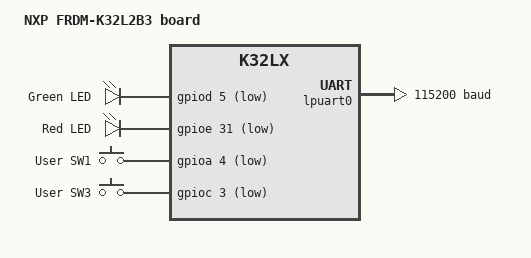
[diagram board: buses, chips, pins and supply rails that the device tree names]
/*
 * SPDX-License-Identifier: Apache-2.0
 */

/dts-v1/;

#include <nxp/nxp_k32l2b3.dtsi>
#include "frdm_k32l2b3-pinctrl.dtsi"
#include <zephyr/dt-bindings/input/input-event-codes.h>

/ {
	model = "NXP FRDM-K32L2B3 board";
	compatible = "nxp,k32l2b3", "nxp,k32lx";

	aliases {
		led0 = &green_led;
		led1 = &red_led;
		sw0 = &sw_1;
		sw1 = &sw_3;
	};

	chosen {
		zephyr,sram = &sram0;
		zephyr,flash = &flash0;
		zephyr,console = &lpuart0;
		zephyr,shell-uart = &lpuart0;
	};

	leds {
		compatible = "gpio-leds";
		green_led: led0 {
			gpios = <&gpiod 5 GPIO_ACTIVE_LOW>;
			label = "Green LED";
		};
		red_led: led1 {
			gpios = <&gpioe 31 GPIO_ACTIVE_LOW>;
			label = "Red LED";
		};
	};

	gpio_keys {
		compatible = "gpio-keys";
		sw_1: sw0 {
			label = "User SW1";
			gpios = <&gpioa 4 GPIO_ACTIVE_LOW>;
			zephyr,code = <INPUT_KEY_0>;
		};
		sw_3: sw1 {
			label = "User SW3";
			gpios = <&gpioc 3 GPIO_ACTIVE_LOW>;
			zephyr,code = <INPUT_KEY_1>;
		};
	};
};

&sim {
	pllfll-select = <KINETIS_SIM_PLLFLLSEL_MCGPLLCLK>;
	er32k-select = <KINETIS_SIM_ER32KSEL_OSC32KCLK>;
};

&cpu0 {
	clock-frequency = <48000000>;
};

&osc {
	clock-frequency = <32768>;
	mode = "low-power";
};

&gpioa {
	status = "okay";
};

&gpiob {
	status = "okay";
};

&gpioc {
	status = "okay";
};

&gpiod {
	status = "okay";
};

&gpioe {
	status = "okay";
};

&lpuart0 {
	status = "okay";
	current-speed = <115200>;
	pinctrl-0 = <&pinmux_lpuart0>;
	pinctrl-names = "default";
};

&lpuart1 {
	status = "disabled";
	current-speed = <115200>;
	pinctrl-0 = <&pinmux_lpuart1>;
	pinctrl-names = "default";
};

&uart2 {
	status = "disabled";
	current-speed = <115200>;
	pinctrl-0 = <&pinmux_uart2>;
	pinctrl-names = "default";
};
